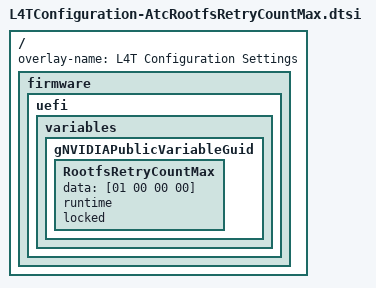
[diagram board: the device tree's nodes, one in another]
/dts-v1/;

/*
 * One boot per trial. The L4T launcher decrements the retry count of the
 * current rootfs slot on every boot. At zero it marks the slot unbootable and
 * boots the other slot. NVIDIA's default is 3 (L4TConfiguration.dts in
 * edk2-nvidia). meta-atc's GRUB backend allows one trial boot, and this
 * overlay gives the Tegra backend the same rule.
 *
 * The flash tools apply the bootcontrol overlays in the order of
 * TEGRA_BOOTCONTROL_OVERLAYS. conf/layer.conf appends this one last,
 * so its value replaces the default.
 */
/ {
        overlay-name = "L4T Configuration Settings";

        fragment@0 {
                target-path = "/";

                board_config {
                        sw-modules = "uefi";
                };

                __overlay__ {
                        firmware {
                                uefi {
                                        variables {
                                                gNVIDIAPublicVariableGuid {
                                                        RootfsRetryCountMax {
                                                                data = [01 00 00 00];
                                                                runtime;
                                                                locked;
                                                        };
                                                };
                                        };
                                };
                        };
                };
        };
};
